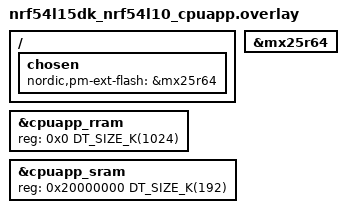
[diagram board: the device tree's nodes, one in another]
/*
 * Copyright (c) 2024 Nordic Semiconductor ASA
 *
 * SPDX-License-Identifier: LicenseRef-Nordic-5-Clause
 */

/ {
	chosen {
		nordic,pm-ext-flash = &mx25r64;
	};
};

/* Application does not use cpuflpr core. Assign whole RRAM and RAM to cpuapp. */
&cpuapp_rram {
	reg = <0x0 DT_SIZE_K(1024)>;
};

&cpuapp_sram {
	reg = <0x20000000 DT_SIZE_K(192)>;
	ranges = <0x0 0x20000000 DT_SIZE_K(192)>;
};

&mx25r64 {
	status = "okay";
};
